VERSION ""

NS_ :

BS_:

BU_: Version HVPP CCU

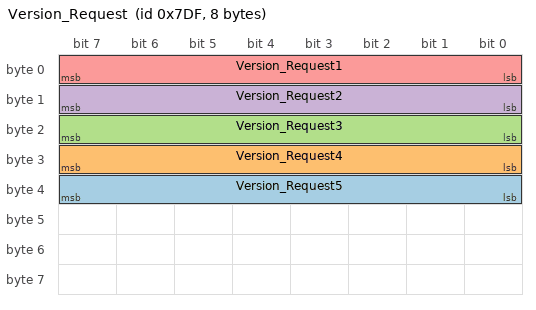
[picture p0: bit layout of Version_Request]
BO_ 2015 Version_Request: 8 Vector__XXX
 SG_ Version_Request5 : 32|8@1- (1,0) [0|0] "" Vector__XXX
 SG_ Version_Request4 : 24|8@1- (1,0) [0|0] "" Vector__XXX
 SG_ Version_Request3 : 16|8@1- (1,0) [0|0] "" Vector__XXX
 SG_ Version_Request2 : 8|8@1- (1,0) [0|0] "" Vector__XXX
 SG_ Version_Request1 : 0|8@1- (1,0) [0|0] "" Vector__XXX

BO_ 1953 Version_Response: 8 Vector__XXX
 SG_ Version_Response_Data : 0|64@1- (1,0) [0|0] "" Vector__XXX
